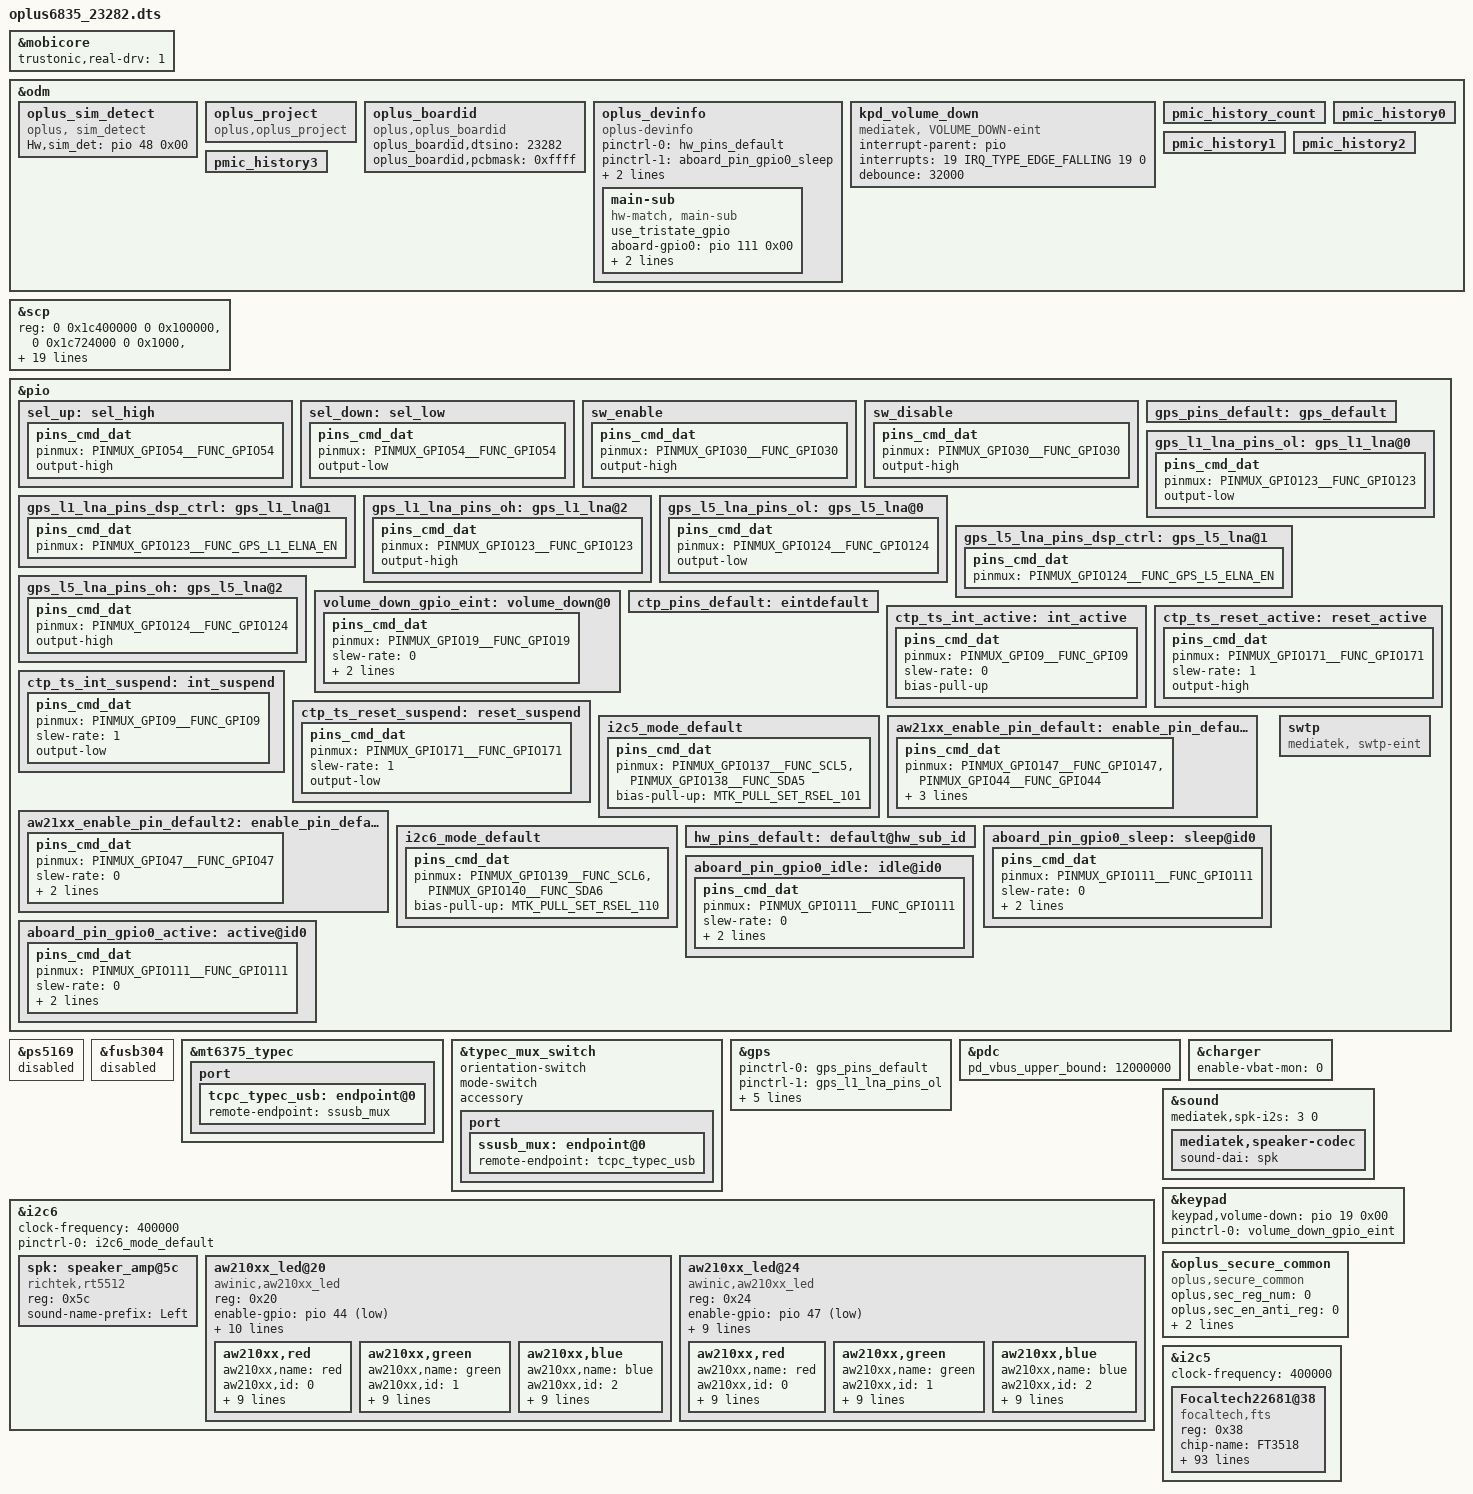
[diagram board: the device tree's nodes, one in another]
// SPDX-License-Identifier: (GPL-2.0 OR MIT)
/*
 * Copyright (C) 2022 MediaTek Inc.
 */
/dts-v1/;
/plugin/;
#include <dt-bindings/interrupt-controller/arm-gic.h>
#include <dt-bindings/interrupt-controller/irq.h>
#include <dt-bindings/phy/phy.h>
#include <dt-bindings/pinctrl/mt6835-pinfunc.h>
#include "mediatek/mt6835_6377.dtsi"
#include "mediatek/oplus_nfc_23282.dtsi"
#include "mediatek/cust_mt6835_camera_23282.dtsi"
#include "mediatek/cust_mt6835_ac176_oled_1080x2400.dtsi"
/* #ifdef OPLUS_FEATURE_CHG_BASIC */
/* Add for DX-2 charge device-tree */
/*#include "mediatek/oplus_charge_23661.dtsi"*/
/* #endif */

/* #ifdef CONFIG_UFF_FINGERPRINT */
#include "mediatek/oplus_uff_23281.dtsi"
/* #endif CONFIG_UFF_FINGERPRINT */

//#ifdef OPLUS_FEATURE_SENSOR
#include "mediatek/oplus_sensor_23282.dtsi"
#include "mediatek/oplus_charge_AvatarMG_45w.dtsi"
#include "mediatek/oplus_charge_AvatarMG_PPS.dtsi"
//#endif
//#ifdef OPLUS_FEATURE_AUDIO
#include "mediatek/cust_mt6835_23281_audio.dtsi"
//#endif
#include "mediatek/oplus_tp_23111.dtsi"

/* Trustonic Mobilecore real driver */
&mobicore{
       trustonic,real-drv = <1>;
};



&odm {
/* Add for sim detect */
    oplus_sim_detect {
        compatible = "oplus, sim_detect";
        Hw,sim_det = <&pio 48 0x00>;
    };
};

&scp {
        reg =   <0 0x1c400000 0 0x100000>, /* tcm */
                <0 0x1c724000 0 0x1000>, /* cfg */
                <0 0x1c721000 0 0x1000>, /* clk*/
                <0 0x1c730000 0 0x1000>, /* cfg core0 */
                <0 0x1c740000 0 0x1000>, /* cfg core1 */
                <0 0x1c752000 0 0x1000>, /* bus tracker */
                <0 0x1c760000 0 0x40000>, /* llc */
                <0 0x1c7a5000 0 0x4>, /* cfg_sec */
                <0 0x1c7fb000 0 0x100>, /* mbox0 base */
                <0 0x1c7fb100 0 0x4>, /* mbox0 set */
                <0 0x1c7fb10c 0 0x4>, /* mbox0 clr */
                <0 0x1c7a5020 0 0x4>, /* mbox0 init */
                <0 0x1c7fc000 0 0x100>, /* mbox1 base */
                <0 0x1c7fc100 0 0x4>, /* mbox1 set */
                <0 0x1c7fc10c 0 0x4>, /* mbox1 clr */
                <0 0x1c7a5024 0 0x4>, /* mbox1 init */
                <0 0x1c7fd000 0 0x100>, /* mbox2 base */
                <0 0x1c7fd100 0 0x4>, /* mbox2 set */
                <0 0x1c7fd10c 0 0x4>, /* mbox2 clr */
                <0 0x1c7a5028 0 0x4>, /* mbox2 init */
                <0 0x1c7fe000 0 0x100>, /* mbox3 base */
                <0 0x1c7fe100 0 0x4>, /* mbox3 set */
                <0 0x1c7fe10c 0 0x4>, /* mbox3 clr */
                <0 0x1c7a502c 0 0x4>, /* mbox3 init */
                <0 0x1c7ff000 0 0x100>, /* mbox4 base */
                <0 0x1c7ff100 0 0x4>, /* mbox4 set */
                <0 0x1c7ff10c 0 0x4>, /* mbox4 clr */
                <0 0x1c7a5030 0 0x4>; /* mbox4 init */
                scp-sramsize = <0x100000>;
                secure-dump-size = <0x500000>;
                memorydump = <0x100000>, /* l2tcm */
                <0x03c000>, /* l1c */
                <0x003c00>, /* regdump */
                <0x000400>, /* trace buffer */
                <0x300000>; /* dram */
};

/* usb typec mux start */
&pio {
	sel_up: sel_high {
		pins_cmd_dat {
			pinmux = <PINMUX_GPIO54__FUNC_GPIO54>;
			output-high;
		};
	};

	sel_down: sel_low  {
		pins_cmd_dat {
			pinmux = <PINMUX_GPIO54__FUNC_GPIO54>;
			output-low;
		};
	};

	sw_enable: sw_enable {
		pins_cmd_dat {
			pinmux = <PINMUX_GPIO30__FUNC_GPIO30>;
			output-high;
		};
	};

	sw_disable: sw_disable {
		pins_cmd_dat {
			pinmux = <PINMUX_GPIO30__FUNC_GPIO30>;
			output-high;
		};
	};
};

&ps5169 {
	status = "disabled";
};

&fusb304 {
	status = "disabled";
};

&mt6375_typec {
	port {
		tcpc_typec_usb: endpoint@0 {
			remote-endpoint = <&ssusb_mux>;
		};
	};
};

&typec_mux_switch {
	orientation-switch;
	mode-switch;
	accessory;
	port {
		ssusb_mux: endpoint@0 {
			remote-endpoint = <&tcpc_typec_usb>;
		};
	};
};
/* usb typec mux end*/

/* GPS GPIO standardization start */
&pio {
	gps_pins_default: gps_default {
	};
	gps_l1_lna_pins_ol: gps_l1_lna@0 {
		pins_cmd_dat {
			pinmux = <PINMUX_GPIO123__FUNC_GPIO123>;
			output-low;
		};
	};
	gps_l1_lna_pins_dsp_ctrl: gps_l1_lna@1 {
		pins_cmd_dat {
			pinmux = <PINMUX_GPIO123__FUNC_GPS_L1_ELNA_EN>;
		};
	};
	gps_l1_lna_pins_oh: gps_l1_lna@2 {
		pins_cmd_dat {
			pinmux = <PINMUX_GPIO123__FUNC_GPIO123>;
			output-high;
		};
	};
	gps_l5_lna_pins_ol: gps_l5_lna@0 {
		pins_cmd_dat {
			pinmux = <PINMUX_GPIO124__FUNC_GPIO124>;
			output-low;
		};
	};
	gps_l5_lna_pins_dsp_ctrl: gps_l5_lna@1 {
		pins_cmd_dat {
			pinmux = <PINMUX_GPIO124__FUNC_GPS_L5_ELNA_EN>;
		};
	};
	gps_l5_lna_pins_oh: gps_l5_lna@2 {
		pins_cmd_dat {
			pinmux = <PINMUX_GPIO124__FUNC_GPIO124>;
			output-high;
		};
	};
};

&gps {
	pinctrl-names = "default",
		"gps_l1_lna_disable",
		"gps_l1_lna_dsp_ctrl",
		"gps_l1_lna_enable",
		"gps_l5_lna_disable",
		"gps_l5_lna_dsp_ctrl",
		"gps_l5_lna_enable";
	pinctrl-0 = <&gps_pins_default>;
	pinctrl-1 = <&gps_l1_lna_pins_ol>;
	pinctrl-2 = <&gps_l1_lna_pins_dsp_ctrl>;
	pinctrl-3 = <&gps_l1_lna_pins_oh>;
	pinctrl-4 = <&gps_l5_lna_pins_ol>;
	pinctrl-5 = <&gps_l5_lna_pins_dsp_ctrl>;
	pinctrl-6 = <&gps_l5_lna_pins_oh>;
	status = "okay";
};
/* GPS GPIO standardization end */


&pdc {
	pd_vbus_upper_bound = <12000000>;
};

&charger{
	enable-vbat-mon = <0>;
};

/*&gpio_keys {
        volumedown {
            label = "Volume_Down";
            linux,code = <114>;
            gpios = <&pio 19 1>;
            wakeup-source;
            debounce-interval = <5>;
        };
};*/
&i2c6 {
	spk: speaker_amp@5c {
		compatible = "richtek,rt5512";
		#sound-dai-cells = <0>;
		reg = <0x5c>;
		status = "okay";
		sound-name-prefix = "Left";
	};
};

&sound {
	mediatek,spk-i2s = <3 0>;
	mediatek,speaker-codec {
		sound-dai = <&spk>;
	};
};


&odm {
/*OPLUS_FEATURE_OEM_OCDT oppo project start */
	oplus_project:oplus_project {
		compatible = "oplus,oplus_project";
	};

	oplus_boardid:oplus_boardid {
		compatible = "oplus,oplus_boardid";
		oplus_boardid,dtsino="23282";//only one u32
		oplus_boardid,pcbmask="0xffff";//all mask 0xffff
	};

	oplus_devinfo:oplus_devinfo {
		compatible = "oplus-devinfo";
		pinctrl-names = "default", "aboard_gpio0_sleep", "aboard_gpio0_active", "aboard_gpio0_idle";
		pinctrl-0 = <&hw_pins_default>;
		pinctrl-1 = <&aboard_pin_gpio0_sleep>;
		pinctrl-2 = <&aboard_pin_gpio0_active>;
		pinctrl-3 = <&aboard_pin_gpio0_idle>;
		main-sub {
			use_tristate_gpio;
			compatible = "hw-match, main-sub";
			aboard-gpio0 = <&pio 111 0x00>;
			aboard-patterns = <2 0>;        /*0[high-resistance] 1[pull-down] 2[pull-up]*/
			/*main board*/
			match-projects = <23281 23282>;
		};
	};

	kpd_volume_down:kpd_volume_down {
		compatible = "mediatek, VOLUME_DOWN-eint";
		interrupt-parent = <&pio>;
		interrupts = <19 IRQ_TYPE_EDGE_FALLING 19 0>;
		debounce = <32000>;
		status = "okay";
	};

	pmic_history_count:pmic_history_count {
	};
	pmic_history0:pmic_history0 {
	};
	pmic_history1:pmic_history1 {
	};
	pmic_history2:pmic_history2 {
	};
	pmic_history3:pmic_history3 {
	};

};
/*endif*/


&keypad {
        keypad,volume-down = <&pio 19 0x00>;
        pinctrl-names = "volume_down_as_int";
        pinctrl-0 = <&volume_down_gpio_eint>;
        status = "okay";
};

&pio {
        volume_down_gpio_eint:volume_down@0{
                pins_cmd_dat {
                        pinmux = <PINMUX_GPIO19__FUNC_GPIO19>;
                        slew-rate = <0>;  /*direction 0:in, 1:out*/
                        input-enable;
                        bias-disable;
                };
        };
};

//#ifdef OPLUS_FEATURE_SECURITY_COMMON
&oplus_secure_common {
	compatible = "oplus,secure_common";
	oplus,sec_reg_num = <0>;
	oplus,sec_en_anti_reg = <0>;
	oplus,sec_override1_reg = <0>;
	oplus,override1_en_value = <0>;
};
//#endif

&i2c5 {
 	status = "okay";
	clock-frequency = <400000>;
 		Focaltech22681@38 {
 		compatible = "focaltech,fts";
 		reg = <0x38>;
 		chip-name = "FT3518";
 
 		/* Interrupt && Irq-gpio */
 		interrupt-parent = <&pio>;
 		interrupts = <9 0x2002>;
 
 		/* Power Config */
 		vdd_2v8-supply  = <&mt6377_vtp>;
 		vdd_2v8_volt = <3000000>;
 
 		/* Other HW Resource */
 		irq-gpio = <&pio 9 0x2002>;
 		reset-gpio = <&pio 171 0x1>;
 		pinctrl-names = "default";
 		pinctrl-0 = <&ctp_ts_int_active &ctp_ts_reset_active &i2c5_mode_default>;
         panel_type = <8>;
 		vid_len = <2>;
 		tp_type = <8>;
		firmware_name = "0xAC17600";
 		// type of tp_dev ,TP-SAMSUNG = 8;
 		platform_support_project = <23281 23282>;
 		platform_support_project_dir = <23281 23281>;
 		platform_support_project_commandline = "ac176_p_1_a0017_fhd_vdo_lcm_drv","ac176_p_1_a0017_fhd_vdo_lcm_drv";
 		touchpanel,max-num-support = <10>;

 		touchpanel,tx-rx-num = <16 34>;
 		touchpanel,panel-coords = <8640 19200>;
 		touchpanel,display-coords = <1080 2400>;
 		touchpanel,touchmajor-limit = <0 54>;
 		touchpanel,report-rate = <120 180>;
 		touchpanel,smooth-level = <255 2 15 25 45 60>;
 		touchpanel,smooth-level-charging = <255 15 20 25 45 60>;
 		touchpanel,sensitive-level = <255 20 17 14 10 8>;
 		touchpanel,single-optimized-time = <8>;

 		//prevention,dead_area_width = <20 20>;
 		//prevention,condition_area_width = <60 60 160 160>;
 		//prevention,eli_area_width = <240 1000 1200 240>;
        prevention,curved_screen_V2;
        prevention,grip_disable_level = <6>;
        prevention,updelay_time_ms = <30>;
        prevention,makeup_cnt_weight = <4 1 2 2 2>;
        prevention,large_corner_range = <960 2400>;
        prevention,large_corner_judge_condition = <500 300 800 7 7>;
        prevention,trx_reject_condition = <8 6 7>;
        prevention,trx_strict_reject_condition = <8 5 6>;
        prevention,large_judge_time_ms = <500 50 30>;
        prevention,large_exit_condition = <8 8 2>;
        prevention,single_channel_width = <160 160>;
        prevention,normal_tap_condition = <10 350>;
        prevention,long_edge_condition = <200 80 180 80>;
        prevention,long_strict_edge_condition = <160 60>;
        prevention,long_fingerhold_condition = <50 6 4 4>;
        prevention,short_edge_condition = <200 80 180 80>;
        prevention,short_strict_edge_condition = <160 60>;
        prevention,large_strict_exit_condition = <4 4>;
        prevention,top_corner_config = <440 1200 360>;
        prevention,edge_swipe_config = <240 960>;

        prevention,curved_screen_V4;
        prevention,long_eliminate_point_type = <2 8640 6400 240 19200 300 1>;
        prevention,long_fingerhold_condition2 = <420 0 0 0>;
        prevention,top_corner_config2 = <3 80 480 0 0>;
        prevention,hor_long_top_corner_config = <240 1600 0 0>;
        prevention,top_middle_config = <8640 800 800 0>;
        prevention,corner_eliminate_point_type = <0 960 1600 1>;
        prevention,finger_hold_differ_size = <1 0 240 300>;
        prevention,finger_hold_max_rx_exit_distance = <5 240 1600>;
        prevention,max_rx_exit_distance = <1 5 150 240 1600>;
        prevention,dynamic_finger_hold_exit_distance = <1 240 1600 360>;
        prevention,edge_sliding_matched_support = <1 150 3 0>;

        /* //grip v4.2 reclining mode
        prevention,reclining_mode_support = <1>;
        prevention,long_eliminate_point_type_recli = <2 8640 6400 80 19200 500 0>;
        prevention,finger_hold_differ_size_recli = <1 0 108 400>;
        prevention,finger_hold_max_rx_exit_distance_recli = <4 60 380>;
        prevention,max_rx_exit_distance_recli = <1 4 100 60 350>;
        prevention,dynamic_finger_hold_exit_distance_recli = <1 60 380 140>;
        prevention,edge_sliding_matched_support_recli = <1 200 3 0>; */

 		/* SW Support Feature Control */
 		black_gesture_support;
		sportify_aod_gesture_support;
 		black_gesture_indep_support;
 		//fw_edge_limit_support;
 		pressure_report_support;
 		charger_pump_support;
 		game_switch_support;
 		smart_gesture_support;
 		fw_update_app_support;
 		fingerprint_underscreen_support;
 		headset_pump_support;
 		//irq_need_dev_resume_ok;
 		health_monitor_support;
 		high_resolution_support;
 		//esd_handle_support;
 		lcd_tp_refresh_support;
		exception_upload_support;
		tp_data_record_support;
		palm_to_sleep_support;
		high_resolution_support_x8;
		kernel_grip_support;
		snr_read_support;
		touchpanel,high-frame-rate-time = <20>;
		temperature_detect_shellback_support;
 		/*
 		 *Virtual Key Config:
 		 *1:touchpanel,button-type: <virtualkey_type  supportted_button-map>
 		 *virtualkey_type:
 		 *Type 1: using board_properties
 		 *Type 2: using same IC (button zone&& touch zone are seprate)
 		 *Type 3: using diffrent IC (button zone&& touch zone are seprate)
 		 *Type 4: No need of virtual key process
 		 *supportted_button-map:select|menu|home|back
 		 *
 		 *2:touchpanel,button-map
 		 *type (X1,Y1)(X2,Y2)(X3,Y3)(Width_X,Hight_Y)--Only when button-type is 0
 		 */
 		touchpanel,button-type = <4>;
 		touchpanel.button-TRx = <0 0>;
 	};
 };

&pio {
 	ctp_pins_default: eintdefault {
 	};
 	ctp_ts_int_active: int_active {
 		pins_cmd_dat {
 			pinmux = <PINMUX_GPIO9__FUNC_GPIO9>;
 			slew-rate = <0>;
 			bias-pull-up;
 		};
 	};
 	ctp_ts_reset_active: reset_active {
 		pins_cmd_dat {
 			pinmux = <PINMUX_GPIO171__FUNC_GPIO171>;
 			slew-rate = <1>;
 			output-high;
 		};
 	};
 	ctp_ts_int_suspend: int_suspend {
 		pins_cmd_dat {
 			pinmux = <PINMUX_GPIO9__FUNC_GPIO9>;
 			slew-rate = <1>;
 			output-low;
 		};
 	};
 	ctp_ts_reset_suspend: reset_suspend {
 		pins_cmd_dat {
 			pinmux = <PINMUX_GPIO171__FUNC_GPIO171>;
 			slew-rate = <1>;
 			output-low;
 		};
 	};

	i2c5_mode_default: i2c5_mode_default {
	pins_cmd_dat {
		pinmux = <PINMUX_GPIO137__FUNC_SCL5>,
				 <PINMUX_GPIO138__FUNC_SDA5>;
			bias-pull-up = <MTK_PULL_SET_RSEL_101>;
		};
	};


};

&i2c6 {
 	status = "okay";
	clock-frequency = <400000>;
	aw210xx_led@20 {
		compatible = "awinic,aw210xx_led";
		reg = <0x20>;

		/* Power Config */
		enable-gpio = <&pio 44 0x1>;
		vbled-enable-gpio = <&pio 147 0x1>;

		aw210xx_led_id = <0>;
		led_groups_num = <8>;
		/* led_allocation_order = <1 3 5 7 2 4 6 8>; */
		led_allocation_order = <1 5 2 6 3 7 0 4>; /* this means place 1st rgb into index 1, 2nd into index 5 and so on*/
		global_current_max = <0x30>;
		global_current_min = <0x0b>;
		osc_clk = <1>;
		br_res = <1>;
		chipid = <0x22>;
		status = "okay";
		pinctrl-names = "default";
		pinctrl-0 = <&aw21xx_enable_pin_default>;
		aw210xx,red {
			aw210xx,name = "red";
			aw210xx,id = <0>;
			aw210xx,imax = <1>;
			aw210xx,led_default_trigger = "none";
			aw210xx,brightness = <0>;
			aw210xx,max-brightness = <255>;
			aw210xx,rise-time-ms = <5>;
			aw210xx,hold-time-ms = <0>;
			aw210xx,fall-time-ms = <0>;
			aw210xx,off-time-ms = <0>;
			aw210xx,color_ratio = <2 3>;
		};
		aw210xx,green {
			aw210xx,name = "green";
			aw210xx,id = <1>;
			aw210xx,imax = <1>;
			aw210xx,led_default_trigger = "none";
			aw210xx,brightness = <0>;
			aw210xx,max-brightness = <255>;
			aw210xx,rise-time-ms = <5>;
			aw210xx,hold-time-ms = <0>;
			aw210xx,fall-time-ms = <0>;
			aw210xx,off-time-ms = <0>;
			aw210xx,color_ratio = <2 3>;
		};
		aw210xx,blue {
			aw210xx,name = "blue";
			aw210xx,id = <2>;
			aw210xx,imax = <1>;
			aw210xx,led_default_trigger = "none";
			aw210xx,brightness = <0>;
			aw210xx,max-brightness = <255>;
			aw210xx,rise-time-ms = <5>;
			aw210xx,hold-time-ms = <0>;
			aw210xx,fall-time-ms = <0>;
			aw210xx,off-time-ms = <0>;
			aw210xx,color_ratio = <1 3>;
		};
	};

	aw210xx_led@24 {
		compatible = "awinic,aw210xx_led";
		reg = <0x24>;
		enable-gpio = <&pio 47 0x1>;
		aw210xx_led_id = <1>;
		led_groups_num = <8>;
		led_allocation_order = <1 3 5 7 2 4 6 8>;
		global_current_max = <0x30>;
		global_current_min = <0x0b>;
		osc_clk = <1>;
		br_res = <1>;
		chipid = <0x22>;
		status = "okay";
		pinctrl-names = "default";
		pinctrl-0 = <&aw21xx_enable_pin_default2>;
		aw210xx,red {
			aw210xx,name = "red";
			aw210xx,id = <0>;
			aw210xx,imax = <1>;
			aw210xx,led_default_trigger = "none";
			aw210xx,brightness = <0>;
			aw210xx,max-brightness = <255>;
			aw210xx,rise-time-ms = <5>;
			aw210xx,hold-time-ms = <0>;
			aw210xx,fall-time-ms = <0>;
			aw210xx,off-time-ms = <0>;
			aw210xx,color_ratio = <2 3>;
		};
		aw210xx,green {
			aw210xx,name = "green";
			aw210xx,id = <1>;
			aw210xx,imax = <1>;
			aw210xx,led_default_trigger = "none";
			aw210xx,brightness = <0>;
			aw210xx,max-brightness = <255>;
			aw210xx,rise-time-ms = <5>;
			aw210xx,hold-time-ms = <0>;
			aw210xx,fall-time-ms = <0>;
			aw210xx,off-time-ms = <0>;
			aw210xx,color_ratio = <2 3>;
		};
		aw210xx,blue {
			aw210xx,name = "blue";
			aw210xx,id = <2>;
			aw210xx,imax = <1>;
			aw210xx,led_default_trigger = "none";
			aw210xx,brightness = <0>;
			aw210xx,max-brightness = <255>;
			aw210xx,rise-time-ms = <5>;
			aw210xx,hold-time-ms = <0>;
			aw210xx,fall-time-ms = <0>;
			aw210xx,off-time-ms = <0>;
			aw210xx,color_ratio = <1 3>;
		};
	};
	
 };

&i2c6 {
	pinctrl-names = "default";
	pinctrl-0 = <&i2c6_mode_default>;
};

&pio{

	 	aw21xx_enable_pin_default: enable_pin_default {
 		pins_cmd_dat {
 			pinmux = <PINMUX_GPIO147__FUNC_GPIO147>,
 					<PINMUX_GPIO44__FUNC_GPIO44>;
 			slew-rate = <0>;
 			bias-disable;
 			input-enable;
 		};
		};
		
		aw21xx_enable_pin_default2: enable_pin_default2 {
		pins_cmd_dat {
			pinmux = <PINMUX_GPIO47__FUNC_GPIO47>;
			slew-rate = <0>;
			bias-disable;
			input-enable;
		};
	};

		i2c6_mode_default: i2c6_mode_default {
		pins_cmd_dat {
			pinmux = <PINMUX_GPIO139__FUNC_SCL6>,
				 <PINMUX_GPIO140__FUNC_SDA6>;
			bias-pull-up = <MTK_PULL_SET_RSEL_110>;
		};
	};
	
};


&pio{
	hw_pins_default:default@hw_sub_id {
	};

	aboard_pin_gpio0_sleep:sleep@id0 {
		pins_cmd_dat {
			pinmux = <PINMUX_GPIO111__FUNC_GPIO111>;
			slew-rate = <0>;
			bias-pull-down;
			input-enable;
		};
	};

	aboard_pin_gpio0_active:active@id0 {
		pins_cmd_dat {
			pinmux = <PINMUX_GPIO111__FUNC_GPIO111>;
			slew-rate = <0>;
			bias-pull-up;
			input-enable;
		};
	};

	aboard_pin_gpio0_idle:idle@id0 {
		pins_cmd_dat {
			pinmux = <PINMUX_GPIO111__FUNC_GPIO111>;
			slew-rate = <0>;
			bias-disable;
			input-enable;
		};
	};
};


//Network RF add SWTP
&pio {
	//#ifdef OPLUS_VENDOR_SWTP
	swtp: swtp {
		compatible = "mediatek, swtp-eint";
	};
	//#endif  /*OPLUS_VENDOR_SWTP*/
};

#include <oplus6835_23282/cust.dtsi>
#include "mediatek/cust_mt6835_barley_thermal.dtsi"
/*#include "mediatek/cust_mt6985_luna_thermal.dtsi"*/
/*End of this file, DO NOT ADD ANYTHING HERE*/
